VERSION ""

NS_ :

BS_:

BU_: KOSTIA_Tester_FA_CAN EGSM

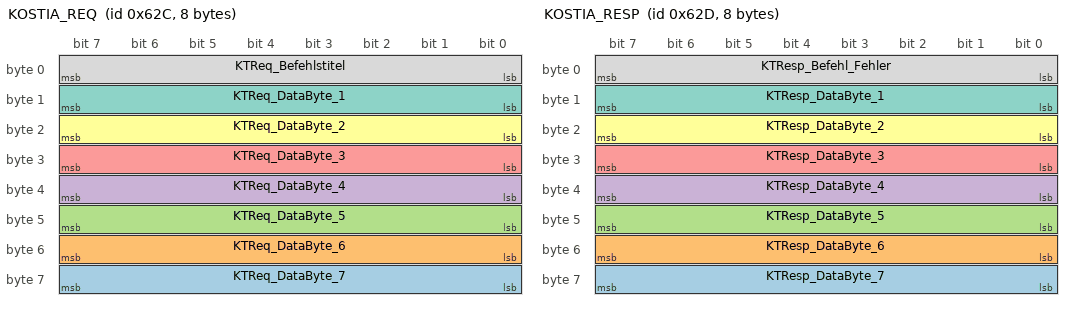
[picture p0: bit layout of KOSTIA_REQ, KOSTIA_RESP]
BO_ 1580 KOSTIA_REQ: 8 KOSTIA_Tester_FA_CAN
 SG_ KTReq_DataByte_7 : 56|8@1+ (1,0) [0|0] ""  EGSM
 SG_ KTReq_DataByte_6 : 48|8@1+ (1,0) [0|0] ""  EGSM
 SG_ KTReq_DataByte_5 : 40|8@1+ (1,0) [0|0] ""  EGSM
 SG_ KTReq_DataByte_4 : 32|8@1+ (1,0) [0|0] ""  EGSM
 SG_ KTReq_DataByte_3 : 24|8@1+ (1,0) [0|0] ""  EGSM
 SG_ KTReq_DataByte_2 : 16|8@1+ (1,0) [0|0] ""  EGSM
 SG_ KTReq_DataByte_1 : 8|8@1+ (1,0) [0|0] ""  EGSM
 SG_ KTReq_Befehlstitel : 0|8@1+ (1,0) [0|0] ""  EGSM

BO_ 1581 KOSTIA_RESP: 8 EGSM
 SG_ KTResp_DataByte_7 : 56|8@1+ (1,0) [0|0] ""  KOSTIA_Tester_FA_CAN
 SG_ KTResp_DataByte_6 : 48|8@1+ (1,0) [0|0] ""  KOSTIA_Tester_FA_CAN
 SG_ KTResp_DataByte_5 : 40|8@1+ (1,0) [0|0] ""  KOSTIA_Tester_FA_CAN
 SG_ KTResp_DataByte_4 : 32|8@1+ (1,0) [0|0] ""  KOSTIA_Tester_FA_CAN
 SG_ KTResp_DataByte_3 : 24|8@1+ (1,0) [0|0] ""  KOSTIA_Tester_FA_CAN
 SG_ KTResp_DataByte_2 : 16|8@1+ (1,0) [0|0] ""  KOSTIA_Tester_FA_CAN
 SG_ KTResp_DataByte_1 : 8|8@1+ (1,0) [0|0] ""  KOSTIA_Tester_FA_CAN
 SG_ KTResp_Befehl_Fehler : 0|8@1+ (1,0) [0|0] ""  KOSTIA_Tester_FA_CAN

EV_ envReadDataFlashProgress: 1 [0|100] "" 0 1 DUMMY_NODE_VECTOR0 Vector__XXX;

EV_ envReadDataFlash: 0 [0|1] "" 0 2 DUMMY_NODE_VECTOR0 Vector__XXX;

EV_ envOutput_RBRstartTest: 0 [0|1] "" 0 3 DUMMY_NODE_VECTOR0 Vector__XXX;

EV_ envRBRDataLabView: 0 [0|0] "" 0 4 DUMMY_NODE_VECTOR0 Vector__XXX;

EV_ EnvRbr_SaveRBRSnapshot_Progress: 1 [0|100] "" 0 5 DUMMY_NODE_VECTOR0 Vector__XXX;

EV_ envCalibMode_CRC: 0 [0|255] "" 0 6 DUMMY_NODE_VECTOR0 Vector__XXX;

EV_ envCalibMode_AliveCnt: 0 [0|255] "" 0 7 DUMMY_NODE_VECTOR0 Vector__XXX;

EV_ envCalibMode_Z2: 1 [-65535|65535] "" 0 8 DUMMY_NODE_VECTOR0 Vector__XXX;

EV_ envCalibMode_Z1: 1 [-65535|65535] "" 0 9 DUMMY_NODE_VECTOR0 Vector__XXX;

EV_ envCalibMode_Y2: 1 [-65535|65535] "" 0 10 DUMMY_NODE_VECTOR0 Vector__XXX;

EV_ envCalibMode_Y1: 1 [-65535|65535] "" 0 11 DUMMY_NODE_VECTOR0 Vector__XXX;

EV_ envCalibMode_X2: 1 [-65535|65535] "" 0 12 DUMMY_NODE_VECTOR0 Vector__XXX;

EV_ envCalibMode_X1: 1 [-65535|65535] "" 0 13 DUMMY_NODE_VECTOR0 Vector__XXX;

EV_ envKostiaCalibModeReq: 0 [0|1] "" 0 14 DUMMY_NODE_VECTOR0 Vector__XXX;

EV_ envKostiaReset: 0 [0|1] "" 0 15 DUMMY_NODE_VECTOR0 Vector__XXX;

EV_ EnvRbr_SaveRBRSnapshot: 0 [0|1] "" 0 16 DUMMY_NODE_VECTOR0 Vector__XXX;

EV_ EnvRbr_Chx2_DataViewCtrl_Gain: 1 [-65535|65535] "" 0 17 DUMMY_NODE_VECTOR0 Vector__XXX;

EV_ EnvRbr_Chx1_DataViewCtrl_Gain: 1 [-65535|65535] "" 0 18 DUMMY_NODE_VECTOR0 Vector__XXX;

EV_ EnvRbr_ReqChannel2: 0 [0|1] "" 1 19 DUMMY_NODE_VECTOR0 Vector__XXX;

EV_ EnvRbr_Chx2_RBR_Version: 0 [0|255] "" 0 20 DUMMY_NODE_VECTOR0 Vector__XXX;

EV_ EnvRbr_Chx2_OverallTransition: 0 [0|255] "" 0 21 DUMMY_NODE_VECTOR0 Vector__XXX;

EV_ EnvRbr_Chx2_OverallError: 0 [0|255] "" 0 22 DUMMY_NODE_VECTOR0 Vector__XXX;

EV_ EnvRbr_Chx2_Mag3DPosDet_Version: 0 [0|255] "" 0 23 DUMMY_NODE_VECTOR8000 Vector__XXX;

EV_ EnvRbr_Chx2_LaneTrInterPosComp: 1 [-255|255] "" 0 24 DUMMY_NODE_VECTOR0 Vector__XXX;

EV_ EnvRbr_Chx2_LaneTrErrorComp: 1 [-65535|65535] "" 0 25 DUMMY_NODE_VECTOR0 Vector__XXX;

EV_ EnvRbr_Chx2_LaneInterPosComp: 1 [-255|255] "" 0 26 DUMMY_NODE_VECTOR0 Vector__XXX;

EV_ EnvRbr_Chx2_LaneErrorComp: 1 [-65535|65535] "" 0 27 DUMMY_NODE_VECTOR0 Vector__XXX;

EV_ EnvRbr_Chx2_DataViewCtrl_Theta: 1 [-65535|65535] "" 0 28 DUMMY_NODE_VECTOR0 Vector__XXX;

EV_ EnvRbr_Chx2_DataViewCtrl_RawZ: 1 [-65535|65535] "" 0 29 DUMMY_NODE_VECTOR0 Vector__XXX;

EV_ EnvRbr_Chx2_DataViewCtrl_RawY: 1 [-65535|65535] "" 0 30 DUMMY_NODE_VECTOR0 Vector__XXX;

EV_ EnvRbr_Chx2_DataViewCtrl_RawX: 1 [-65535|65535] "" 0 31 DUMMY_NODE_VECTOR0 Vector__XXX;

EV_ EnvRbr_Chx2_DataViewCtrl_Pos: 0 [0|255] "" 0 32 DUMMY_NODE_VECTOR0 Vector__XXX;

EV_ EnvRbr_Chx2_DataViewCtrl_Phi: 1 [-65535|65535] "" 0 33 DUMMY_NODE_VECTOR0 Vector__XXX;

EV_ EnvRbr_Chx2_DataViewCtrl_DebPos: 0 [0|255] "" 0 34 DUMMY_NODE_VECTOR0 Vector__XXX;

EV_ EnvRbr_Chx2_CalibTipUp_Theta: 1 [-65535|65535] "" 0 35 DUMMY_NODE_VECTOR0 Vector__XXX;

EV_ EnvRbr_Chx2_CalibTipUp_Phi: 1 [-65535|65535] "" 0 36 DUMMY_NODE_VECTOR0 Vector__XXX;

EV_ EnvRbr_Chx2_CalibTipRight_Theta: 1 [-65535|65535] "" 0 37 DUMMY_NODE_VECTOR0 Vector__XXX;

EV_ EnvRbr_Chx2_CalibTipRight_Phi: 1 [-65535|65535] "" 0 38 DUMMY_NODE_VECTOR0 Vector__XXX;

EV_ EnvRbr_Chx2_CalibTipLeft_Theta: 1 [-65535|65535] "" 0 39 DUMMY_NODE_VECTOR0 Vector__XXX;

EV_ EnvRbr_Chx2_CalibTipLeft_Phi: 1 [-65535|65535] "" 0 40 DUMMY_NODE_VECTOR0 Vector__XXX;

EV_ EnvRbr_Chx2_CalibTipDown_Theta: 1 [-65535|65535] "" 0 41 DUMMY_NODE_VECTOR0 Vector__XXX;

EV_ EnvRbr_Chx2_CalibTipDown_Phi: 1 [-65535|65535] "" 0 42 DUMMY_NODE_VECTOR0 Vector__XXX;

EV_ EnvRbr_Chx2_CalibNeutral_Theta: 1 [-65535|65535] "" 0 43 DUMMY_NODE_VECTOR0 Vector__XXX;

EV_ EnvRbr_Chx2_CalibNeutral_Phi: 1 [-65535|65535] "" 0 44 DUMMY_NODE_VECTOR0 Vector__XXX;

EV_ EnvRbr_ReqChannel1: 0 [0|1] "" 1 45 DUMMY_NODE_VECTOR0 Vector__XXX;

EV_ EnvRbr_Chx1_CalibTipRight_Phi: 1 [-65535|65535] "" 0 46 DUMMY_NODE_VECTOR0 Vector__XXX;

EV_ EnvRbr_Chx1_CalibTipUp_Theta: 1 [-65535|65535] "" 0 47 DUMMY_NODE_VECTOR0 Vector__XXX;

EV_ EnvRbr_Chx1_CalibTipRight_Theta: 1 [-65535|65535] "" 0 48 DUMMY_NODE_VECTOR0 Vector__XXX;

EV_ EnvRbr_Chx1_CalibTipLeft_Theta: 1 [-65535|65535] "" 0 49 DUMMY_NODE_VECTOR0 Vector__XXX;

EV_ EnvRbr_Chx1_CalibTipDown_Theta: 1 [-65535|65535] "" 0 50 DUMMY_NODE_VECTOR0 Vector__XXX;

EV_ EnvRbr_Chx1_CalibNeutral_Theta: 1 [-65535|65535] "" 0 51 DUMMY_NODE_VECTOR0 Vector__XXX;

EV_ EnvRbr_Chx1_CalibTipLeft_Phi: 1 [-65535|65535] "" 0 52 DUMMY_NODE_VECTOR0 Vector__XXX;

EV_ EnvRbr_Chx1_CalibTipDown_Phi: 1 [-65535|65535] "" 0 53 DUMMY_NODE_VECTOR0 Vector__XXX;

EV_ EnvRbr_Chx1_CalibTipUp_Phi: 1 [-65535|65535] "" 0 54 DUMMY_NODE_VECTOR0 Vector__XXX;

EV_ EnvRbr_Chx1_CalibNeutral_Phi: 1 [-65535|65535] "" 0 55 DUMMY_NODE_VECTOR0 Vector__XXX;

EV_ EnvRbr_Chx1_RBR_Version: 0 [0|255] "" 0 56 DUMMY_NODE_VECTOR0 Vector__XXX;

EV_ EnvRbr_Chx1_OverallTransition: 0 [0|255] "" 0 57 DUMMY_NODE_VECTOR0 Vector__XXX;

EV_ EnvRbr_Chx1_OverallError: 0 [0|255] "" 0 58 DUMMY_NODE_VECTOR0 Vector__XXX;

EV_ EnvRbr_Chx1_LaneTrErrorComp: 1 [-65535|65535] "" 0 59 DUMMY_NODE_VECTOR0 Vector__XXX;

EV_ EnvRbr_Chx1_LaneErrorComp: 1 [-65535|65535] "" 0 60 DUMMY_NODE_VECTOR0 Vector__XXX;

EV_ EnvRbr_Chx1_LaneTrInterPosComp: 1 [-255|255] "" 0 61 DUMMY_NODE_VECTOR0 Vector__XXX;

EV_ EnvRbr_Chx1_LaneInterPosComp: 1 [-255|255] "" 0 62 DUMMY_NODE_VECTOR0 Vector__XXX;

EV_ EnvRbr_Chx1_DataViewCtrl_RawZ: 1 [-65535|65535] "" 0 63 DUMMY_NODE_VECTOR0 Vector__XXX;

EV_ EnvRbr_Chx1_DataViewCtrl_RawY: 1 [-65535|65535] "" 0 64 DUMMY_NODE_VECTOR0 Vector__XXX;

EV_ EnvRbr_Chx1_DataViewCtrl_RawX: 1 [-65535|65535] "" 0 65 DUMMY_NODE_VECTOR0 Vector__XXX;

EV_ EnvRbr_Chx1_DataViewCtrl_Theta: 1 [-65535|65535] "" 0 66 DUMMY_NODE_VECTOR0 Vector__XXX;

EV_ EnvRbr_Chx1_DataViewCtrl_Phi: 1 [-65535|65535] "" 0 67 DUMMY_NODE_VECTOR0 Vector__XXX;

EV_ EnvRbr_Chx1_DataViewCtrl_Pos: 0 [0|255] "" 0 68 DUMMY_NODE_VECTOR0 Vector__XXX;

EV_ EnvRbr_Chx1_DataViewCtrl_DebPos: 0 [0|255] "" 0 69 DUMMY_NODE_VECTOR0 Vector__XXX;

EV_ EnvRbr_Chx1_Mag3DPosDet_Version: 0 [0|255] "" 0 70 DUMMY_NODE_VECTOR8000 Vector__XXX;

EV_ EnvRbr_DataViewControl: 0 [0|1] "" 0 71 DUMMY_NODE_VECTOR0 Vector__XXX;

EV_ EnvRbr_Init: 0 [0|1] "" 0 72 DUMMY_NODE_VECTOR0 Vector__XXX;

EV_ EnvRbr_CtrlByte2: 0 [0|255] "" 0 73 DUMMY_NODE_VECTOR0 Vector__XXX;

EV_ EnvRbr_CtrlByte1: 0 [0|255] "" 0 74 DUMMY_NODE_VECTOR0 Vector__XXX;

EV_ EnvRbr_CtrlByte0: 0 [0|255] "" 0 75 DUMMY_NODE_VECTOR0 Vector__XXX;

EV_ EnvRbr_CyclicOn: 0 [0|1] "" 0 76 DUMMY_NODE_VECTOR0 Vector__XXX;

EV_ envKostiaStoreCalibNvram: 0 [0|1] "" 0 77 DUMMY_NODE_VECTOR0 Vector__XXX;

EV_ envKostiaModeSleep2Req: 0 [0|1] "" 0 78 DUMMY_NODE_VECTOR0 Vector__XXX;

EV_ envKostiaModeNormalReq: 0 [0|1] "" 0 79 DUMMY_NODE_VECTOR0 Vector__XXX;

EV_ envKostiaDeactivate: 0 [0|1] "" 0 80 DUMMY_NODE_VECTOR0 Vector__XXX;

EV_ EnvMag3DPosDet_DeCalibRequest: 0 [0|1] "" 0 81 DUMMY_NODE_VECTOR0 Vector__XXX;

EV_ EnvRbrPgSelect_Mag3DPosDet_High: 0 [0|1] "" 0 82 DUMMY_NODE_VECTOR0 Vector__XXX;

EV_ EnvRbrPgSelect_Mag3DPosDet_Fast2: 0 [0|1] "" 0 83 DUMMY_NODE_VECTOR0 Vector__XXX;

EV_ EnvRbrPgSelect_Mag3DPosDet_Fast1: 0 [0|1] "" 0 84 DUMMY_NODE_VECTOR0 Vector__XXX;

EV_ EnvRbr_Snapshot: 0 [0|1] "" 0 85 DUMMY_NODE_VECTOR0 Vector__XXX;

EV_ EnvMag3DPosDet_RbrSnapshot: 0 [0|1] "" 0 86 DUMMY_NODE_VECTOR0 Vector__XXX;

EV_ EnvMag3DPosDet_CalibRequestMMin: 0 [0|1] "" 0 87 DUMMY_NODE_VECTOR0 Vector__XXX;

EV_ EnvMag3DPosDet_CalibRequestMPlus: 0 [0|1] "" 0 88 DUMMY_NODE_VECTOR0 Vector__XXX;

EV_ EnvMag3DPosDet_CalibRequestB: 0 [0|1] "" 0 89 DUMMY_NODE_VECTOR0 Vector__XXX;

EV_ EnvMag3DPosDet_CalibRequestF: 0 [0|1] "" 0 90 DUMMY_NODE_VECTOR0 Vector__XXX;

EV_ EnvMag3DPosDet_CalibRequestN: 0 [0|1] "" 0 91 DUMMY_NODE_VECTOR0 Vector__XXX;

EV_ EnvMag3DPosDet_CalibPositionText: 0 [0|0] "" 0 92 DUMMY_NODE_VECTOR8000 Vector__XXX;

EV_ EnvMag3DPosDet_CalibPosition: 0 [0|9] "" 1 93 DUMMY_NODE_VECTOR0 Vector__XXX;

EV_ envKostiaTextWindow2: 0 [0|0] "" 0 94 DUMMY_NODE_VECTOR8000 Vector__XXX;

EV_ envKostiaTextWindow1: 0 [0|0] "" 0 95 DUMMY_NODE_VECTOR8000 Vector__XXX;

EV_ envKostiaLogoutRequest: 0 [0|1] "" 0 96 DUMMY_NODE_VECTOR0 Vector__XXX;

EV_ envKostiaLoginRequest: 0 [0|1] "" 0 97 DUMMY_NODE_VECTOR0 Vector__XXX;
ENVVAR_DATA_ envRBRDataLabView: 200;

CM_ BU_ KOSTIA_Tester_FA_CAN "EOL in production KOSTAL worldwide";
CM_ BU_ EGSM "VCC CMA EGSM";
BA_DEF_  "Manufacturer" ENUM  "DBAG","VAG","BMWAG","VCC";
BA_DEF_  "NmAsrTimeoutTime" INT 0 65535;
BA_DEF_  "NmAsrWaitBusSleepTime" INT 0 65535;
BA_DEF_  "NmAsrRepeatMessageTime" INT 0 65535;
BA_DEF_  "NmAsrCanMsgCycleTime" INT 0 65535;
BA_DEF_  "NmAsrCanMsgTxTimeoutTime" INT 0 65535;
BA_DEF_  "NmAsrBaseAddress" HEX 0 2047;
BA_DEF_  "NmAsrMessageCount" INT 1 255;
BA_DEF_  "NmType" STRING ;
BA_DEF_ BO_  "DiagRequest" ENUM  "no","yes";
BA_DEF_ BO_  "DiagResponse" ENUM  "no","yes";
BA_DEF_ BO_  "Message_Longname" STRING ;
BA_DEF_ BO_  "RequestMessage" ENUM  "no","yes";
BA_DEF_ BO_  "NmAsrMessage" ENUM  "no","yes";
BA_DEF_ BO_  "AddRemark" STRING ;
BA_DEF_ BO_  "GenMsgCycleTime" INT 0 1000000;
BA_DEF_ BO_  "GenMsgDelayTime" INT 0 1000000;
BA_DEF_ BO_  "GenMsgSendType" ENUM  "Zyklisch","Ereignisgesteuert","Auf Anfrage","dummy";
BA_DEF_ BO_  "AddRemark2" STRING ;
BA_DEF_ BO_  "GenMsgSendType2" ENUM  "Zyklisch","Ereignisgesteuert","Auf Anfrage","dummy";
BA_DEF_ BO_  "AddRemark3" STRING ;
BA_DEF_ BO_  "GenMsgSendType3" ENUM  "Zyklisch","Ereignisgesteuert","Auf Anfrage","dummy";
BA_DEF_ BO_  "AddRemark4" STRING ;
BA_DEF_ BO_  "GenMsgSendType4" ENUM  "Zyklisch","Ereignisgesteuert","Auf Anfrage","dummy";
BA_DEF_ BO_  "GenMsgSendType5" ENUM  "Zyklisch","Ereignisgesteuert","Auf Anfrage","dummy";
BA_DEF_ BO_  "GenMsgSendType6" ENUM  "Zyklisch","Ereignisgesteuert","Auf Anfrage","dummy";
BA_DEF_ BO_  "GenMsgSendType7" ENUM  "Zyklisch","Ereignisgesteuert","Auf Anfrage","dummy";
BA_DEF_ BO_  "GenMsgSendType8" ENUM  "Zyklisch","Ereignisgesteuert","Auf Anfrage","dummy";
BA_DEF_ BO_  "GenMsgSendType9" ENUM  "Zyklisch","Ereignisgesteuert","Auf Anfrage","dummy";
BA_DEF_ BO_  "GenMsgSendType10" ENUM  "Zyklisch","Ereignisgesteuert","Auf Anfrage","dummy";
BA_DEF_ BO_  "GenMsgSendType11" ENUM  "Zyklisch","Ereignisgesteuert","Auf Anfrage","dummy";
BA_DEF_ BO_  "GenMsgSendType12" ENUM  "Zyklisch","Ereignisgesteuert","Auf Anfrage","dummy";
BA_DEF_ BO_  "GenMsgSendType13" ENUM  "Zyklisch","Ereignisgesteuert","Auf Anfrage","dummy";
BA_DEF_ BO_  "GenMsgSendType14" ENUM  "Zyklisch","Ereignisgesteuert","Auf Anfrage","dummy";
BA_DEF_ BO_  "GenMsgSendType15" ENUM  "Zyklisch","Ereignisgesteuert","Auf Anfrage","dummy";
BA_DEF_ BO_  "GenMsgSendType16" ENUM  "Zyklisch","Ereignisgesteuert","Auf Anfrage","dummy";
BA_DEF_ BO_  "GenMsgSendType17" ENUM  "Zyklisch","Ereignisgesteuert","Auf Anfrage","dummy";
BA_DEF_ BO_  "GenMsgSendType18" ENUM  "Zyklisch","Ereignisgesteuert","Auf Anfrage","dummy";
BA_DEF_ BO_  "GenMsgSendType19" ENUM  "Zyklisch","Ereignisgesteuert","Auf Anfrage","dummy";
BA_DEF_ BO_  "GenMsgSendType20" ENUM  "Zyklisch","Ereignisgesteuert","Auf Anfrage","dummy";
BA_DEF_ BO_  "GenMsgSendType21" ENUM  "Zyklisch","Ereignisgesteuert","Auf Anfrage","dummy";
BA_DEF_ BO_  "GenMsgSendType22" ENUM  "Zyklisch","Ereignisgesteuert","Auf Anfrage","dummy";
BA_DEF_ BO_  "GenMsgSendType23" ENUM  "Zyklisch","Ereignisgesteuert","Auf Anfrage","dummy";
BA_DEF_ BO_  "GenMsgSendType24" ENUM  "Zyklisch","Ereignisgesteuert","Auf Anfrage","dummy";
BA_DEF_ BO_  "GenMsgSendType25" ENUM  "Zyklisch","Ereignisgesteuert","Auf Anfrage","dummy";
BA_DEF_ BO_  "GenMsgSendType26" ENUM  "Zyklisch","Ereignisgesteuert","Auf Anfrage","dummy";
BA_DEF_ BO_  "GenMsgSendType27" ENUM  "Zyklisch","Ereignisgesteuert","Auf Anfrage","dummy";
BA_DEF_ BO_  "GenMsgSendType28" ENUM  "Zyklisch","Ereignisgesteuert","Auf Anfrage","dummy";
BA_DEF_ BO_  "GenMsgSendType29" ENUM  "Zyklisch","Ereignisgesteuert","Auf Anfrage","dummy";
BA_DEF_ BO_  "GenMsgSendType30" ENUM  "Zyklisch","Ereignisgesteuert","Auf Anfrage","dummy";
BA_DEF_ BO_  "GenMsgSendType31" ENUM  "Zyklisch","Ereignisgesteuert","Auf Anfrage","dummy";
BA_DEF_ BO_  "GenMsgSendType32" ENUM  "Zyklisch","Ereignisgesteuert","Auf Anfrage","dummy";
BA_DEF_ BO_  "GenMsgSendType33" ENUM  "Zyklisch","Ereignisgesteuert","Auf Anfrage","dummy";
BA_DEF_ BO_  "GenMsgSendType34" ENUM  "Zyklisch","Ereignisgesteuert","Auf Anfrage","dummy";
BA_DEF_ BO_  "GenMsgSendType35" ENUM  "Zyklisch","Ereignisgesteuert","Auf Anfrage","dummy";
BA_DEF_ BO_  "GenMsgSendType36" ENUM  "Zyklisch","Ereignisgesteuert","Auf Anfrage","dummy";
BA_DEF_ BO_  "GenMsgSendType37" ENUM  "Zyklisch","Ereignisgesteuert","Auf Anfrage","dummy";
BA_DEF_ BO_  "GenMsgSendType38" ENUM  "Zyklisch","Ereignisgesteuert","Auf Anfrage","dummy";
BA_DEF_ BO_  "GenMsgSendType39" ENUM  "Zyklisch","Ereignisgesteuert","Auf Anfrage","dummy";
BA_DEF_ BU_  "ECU_Longname" STRING ;
BA_DEF_ BU_  "MCV-Nummer" STRING ;
BA_DEF_ BU_  "DiagnoseStationsAdresse" HEX 0 255;
BA_DEF_ BU_  "MessageManagerUsed" ENUM  "no","yes";
BA_DEF_ BU_  "NodeLayerModules" STRING ;
BA_DEF_ BU_  "NmAsrCanMsgCycleOffset" INT 0 65535;
BA_DEF_ BU_  "NmAsrCanMsgReducedTime" INT 0 65535;
BA_DEF_ BU_  "NmAsrNodeIdentifier" HEX 0 255;
BA_DEF_ BU_  "NmAsrNode" ENUM  "no","yes";
BA_DEF_ SG_  "Signal_Name_English" STRING ;
BA_DEF_ SG_  "Signal_Name_German" STRING ;
BA_DEF_DEF_  "Manufacturer" "VCC";
BA_DEF_DEF_  "NmAsrTimeoutTime" 2000;
BA_DEF_DEF_  "NmAsrWaitBusSleepTime" 1500;
BA_DEF_DEF_  "NmAsrRepeatMessageTime" 3200;
BA_DEF_DEF_  "NmAsrCanMsgCycleTime" 640;
BA_DEF_DEF_  "NmAsrCanMsgTxTimeoutTime" 1920;
BA_DEF_DEF_  "NmAsrBaseAddress" 1280;
BA_DEF_DEF_  "NmAsrMessageCount" 128;
BA_DEF_DEF_  "NmType" "NmAsr";
BA_DEF_DEF_  "DiagRequest" "no";
BA_DEF_DEF_  "DiagResponse" "no";
BA_DEF_DEF_  "Message_Longname" "";
BA_DEF_DEF_  "RequestMessage" "no";
BA_DEF_DEF_  "NmAsrMessage" "no";
BA_DEF_DEF_  "AddRemark" "";
BA_DEF_DEF_  "GenMsgCycleTime" 0;
BA_DEF_DEF_  "GenMsgDelayTime" 0;
BA_DEF_DEF_  "GenMsgSendType" "Zyklisch";
BA_DEF_DEF_  "AddRemark2" "";
BA_DEF_DEF_  "GenMsgSendType2" "Zyklisch";
BA_DEF_DEF_  "AddRemark3" "";
BA_DEF_DEF_  "GenMsgSendType3" "Zyklisch";
BA_DEF_DEF_  "AddRemark4" "";
BA_DEF_DEF_  "GenMsgSendType4" "Zyklisch";
BA_DEF_DEF_  "GenMsgSendType5" "Zyklisch";
BA_DEF_DEF_  "GenMsgSendType6" "Zyklisch";
BA_DEF_DEF_  "GenMsgSendType7" "Zyklisch";
BA_DEF_DEF_  "GenMsgSendType8" "Zyklisch";
BA_DEF_DEF_  "GenMsgSendType9" "Zyklisch";
BA_DEF_DEF_  "GenMsgSendType10" "Zyklisch";
BA_DEF_DEF_  "GenMsgSendType11" "Zyklisch";
BA_DEF_DEF_  "GenMsgSendType12" "Zyklisch";
BA_DEF_DEF_  "GenMsgSendType13" "Zyklisch";
BA_DEF_DEF_  "GenMsgSendType14" "Zyklisch";
BA_DEF_DEF_  "GenMsgSendType15" "Zyklisch";
BA_DEF_DEF_  "GenMsgSendType16" "Zyklisch";
BA_DEF_DEF_  "GenMsgSendType17" "Zyklisch";
BA_DEF_DEF_  "GenMsgSendType18" "Zyklisch";
BA_DEF_DEF_  "GenMsgSendType19" "Zyklisch";
BA_DEF_DEF_  "GenMsgSendType20" "Zyklisch";
BA_DEF_DEF_  "GenMsgSendType21" "Zyklisch";
BA_DEF_DEF_  "GenMsgSendType22" "Zyklisch";
BA_DEF_DEF_  "GenMsgSendType23" "Zyklisch";
BA_DEF_DEF_  "GenMsgSendType24" "Zyklisch";
BA_DEF_DEF_  "GenMsgSendType25" "Zyklisch";
BA_DEF_DEF_  "GenMsgSendType26" "Zyklisch";
BA_DEF_DEF_  "GenMsgSendType27" "Zyklisch";
BA_DEF_DEF_  "GenMsgSendType28" "Zyklisch";
BA_DEF_DEF_  "GenMsgSendType29" "Zyklisch";
BA_DEF_DEF_  "GenMsgSendType30" "Zyklisch";
BA_DEF_DEF_  "GenMsgSendType31" "Zyklisch";
BA_DEF_DEF_  "GenMsgSendType32" "Zyklisch";
BA_DEF_DEF_  "GenMsgSendType33" "Zyklisch";
BA_DEF_DEF_  "GenMsgSendType34" "Zyklisch";
BA_DEF_DEF_  "GenMsgSendType35" "Zyklisch";
BA_DEF_DEF_  "GenMsgSendType36" "Zyklisch";
BA_DEF_DEF_  "GenMsgSendType37" "Zyklisch";
BA_DEF_DEF_  "GenMsgSendType38" "Zyklisch";
BA_DEF_DEF_  "GenMsgSendType39" "Zyklisch";
BA_DEF_DEF_  "ECU_Longname" "";
BA_DEF_DEF_  "MCV-Nummer" "";
BA_DEF_DEF_  "DiagnoseStationsAdresse" 0;
BA_DEF_DEF_  "MessageManagerUsed" "yes";
BA_DEF_DEF_  "NodeLayerModules" "AsrNM_BMW.dll";
BA_DEF_DEF_  "NmAsrCanMsgCycleOffset" 0;
BA_DEF_DEF_  "NmAsrCanMsgReducedTime" 640;
BA_DEF_DEF_  "NmAsrNodeIdentifier" 0;
BA_DEF_DEF_  "NmAsrNode" "no";
BA_DEF_DEF_  "Signal_Name_English" "";
BA_DEF_DEF_  "Signal_Name_German" "";
BA_ "NodeLayerModules" BU_ KOSTIA_Tester_FA_CAN "";
BA_ "MCV-Nummer" BU_ KOSTIA_Tester_FA_CAN "0";
BA_ "MessageManagerUsed" BU_ KOSTIA_Tester_FA_CAN 0;
BA_ "ECU_Longname" BU_ KOSTIA_Tester_FA_CAN "KOSTIA_Tester_FA_CAN";
BA_ "NodeLayerModules" BU_ EGSM "";
BA_ "MCV-Nummer" BU_ EGSM "0";
BA_ "MessageManagerUsed" BU_ EGSM 0;
BA_ "ECU_Longname" BU_ EGSM "Electronic Gear Shift Module";
BA_ "AddRemark" BO_ 1580 "*";
BA_ "GenMsgSendType" BO_ 1580 1;
BA_ "AddRemark2" BO_ 1580 "*";
BA_ "AddRemark3" BO_ 1580 "*";
BA_ "AddRemark4" BO_ 1580 "*";
BA_ "Message_Longname" BO_ 1580 "Kostia Request Frame";
BA_ "AddRemark" BO_ 1581 "*";
BA_ "GenMsgSendType" BO_ 1581 1;
BA_ "AddRemark2" BO_ 1581 "*";
BA_ "AddRemark3" BO_ 1581 "*";
BA_ "AddRemark4" BO_ 1581 "*";
BA_ "Message_Longname" BO_ 1581 "Kostia Response Frame";
BA_ "Signal_Name_English" SG_ 1580 KTReq_DataByte_7 "Request Data Byte 7";
BA_ "Signal_Name_German" SG_ 1580 KTReq_DataByte_7 "Anforderung Datenbyte 7";
BA_ "Signal_Name_English" SG_ 1580 KTReq_DataByte_6 "Request Data Byte 6";
BA_ "Signal_Name_German" SG_ 1580 KTReq_DataByte_6 "Anforderung Datenbyte 6";
BA_ "Signal_Name_English" SG_ 1580 KTReq_DataByte_5 "Request Data Byte 5";
BA_ "Signal_Name_German" SG_ 1580 KTReq_DataByte_5 "Anforderung Datenbyte 5";
BA_ "Signal_Name_English" SG_ 1580 KTReq_DataByte_4 "Request Data Byte 4";
BA_ "Signal_Name_German" SG_ 1580 KTReq_DataByte_4 "Anforderung Datenbyte 4";
BA_ "Signal_Name_English" SG_ 1580 KTReq_DataByte_3 "Request Data Byte 3";
BA_ "Signal_Name_German" SG_ 1580 KTReq_DataByte_3 "Anforderung Datenbyte 3";
BA_ "Signal_Name_English" SG_ 1580 KTReq_DataByte_2 "Request Data Byte 2";
BA_ "Signal_Name_German" SG_ 1580 KTReq_DataByte_2 "Anforderung Datenbyte 2";
BA_ "Signal_Name_English" SG_ 1580 KTReq_DataByte_1 "Request Data Byte 1";
BA_ "Signal_Name_German" SG_ 1580 KTReq_DataByte_1 "Anforderung Datenbyte 1";
BA_ "Signal_Name_English" SG_ 1580 KTReq_Befehlstitel "Request Command title";
BA_ "Signal_Name_German" SG_ 1580 KTReq_Befehlstitel "Anforderung Befehlstitel";
BA_ "Signal_Name_English" SG_ 1581 KTResp_DataByte_7 "Response Data Byte 7";
BA_ "Signal_Name_German" SG_ 1581 KTResp_DataByte_7 "Antwort Datenbyte 7";
BA_ "Signal_Name_English" SG_ 1581 KTResp_DataByte_6 "Response Data Byte 6";
BA_ "Signal_Name_German" SG_ 1581 KTResp_DataByte_6 "Antwort Datenbyte 6";
BA_ "Signal_Name_English" SG_ 1581 KTResp_DataByte_5 "Response Data Byte 5";
BA_ "Signal_Name_German" SG_ 1581 KTResp_DataByte_5 "Antwort Datenbyte 5";
BA_ "Signal_Name_English" SG_ 1581 KTResp_DataByte_4 "Response Data Byte 4";
BA_ "Signal_Name_German" SG_ 1581 KTResp_DataByte_4 "Antwort Datenbyte 4";
BA_ "Signal_Name_English" SG_ 1581 KTResp_DataByte_3 "Response Data Byte 3";
BA_ "Signal_Name_German" SG_ 1581 KTResp_DataByte_3 "Antwort Datenbyte 3";
BA_ "Signal_Name_English" SG_ 1581 KTResp_DataByte_2 "Response Data Byte 2";
BA_ "Signal_Name_German" SG_ 1581 KTResp_DataByte_2 "Antwort Datenbyte 2";
BA_ "Signal_Name_English" SG_ 1581 KTResp_DataByte_1 "Response Data Byte 1";
BA_ "Signal_Name_German" SG_ 1581 KTResp_DataByte_1 "Antwort Datenbyte 1";
BA_ "Signal_Name_English" SG_ 1581 KTResp_Befehl_Fehler "Response Command or Error";
BA_ "Signal_Name_German" SG_ 1581 KTResp_Befehl_Fehler "Antwort Befehl oder Fehler";
